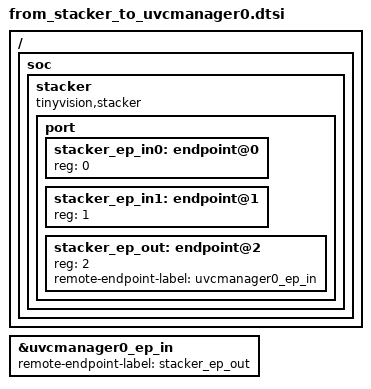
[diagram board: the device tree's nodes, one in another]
/*
 * Copyright (c) 2025 tinyVision.ai Inc.
 *
 * SPDX-License-Identifier: Apache-2.0
 */

#include <riscv/tinyvision/add_stacker.dtsi>
#include <riscv/tinyvision/add_uvcmanager0.dtsi>

/ {
	soc {
		stacker: stacker {
			compatible = "tinyvision,stacker";

			port {
				stacker_ep_in0: endpoint@0 {
					reg = <0>;
				};

				stacker_ep_in1: endpoint@1 {
					reg = <1>;
				};

				stacker_ep_out: endpoint@2 {
					reg = <2>;
				};
			};
		};
	};
};

&stacker_ep_out {
	remote-endpoint-label = "uvcmanager0_ep_in";
};

&uvcmanager0_ep_in {
	remote-endpoint-label = "stacker_ep_out";
};
